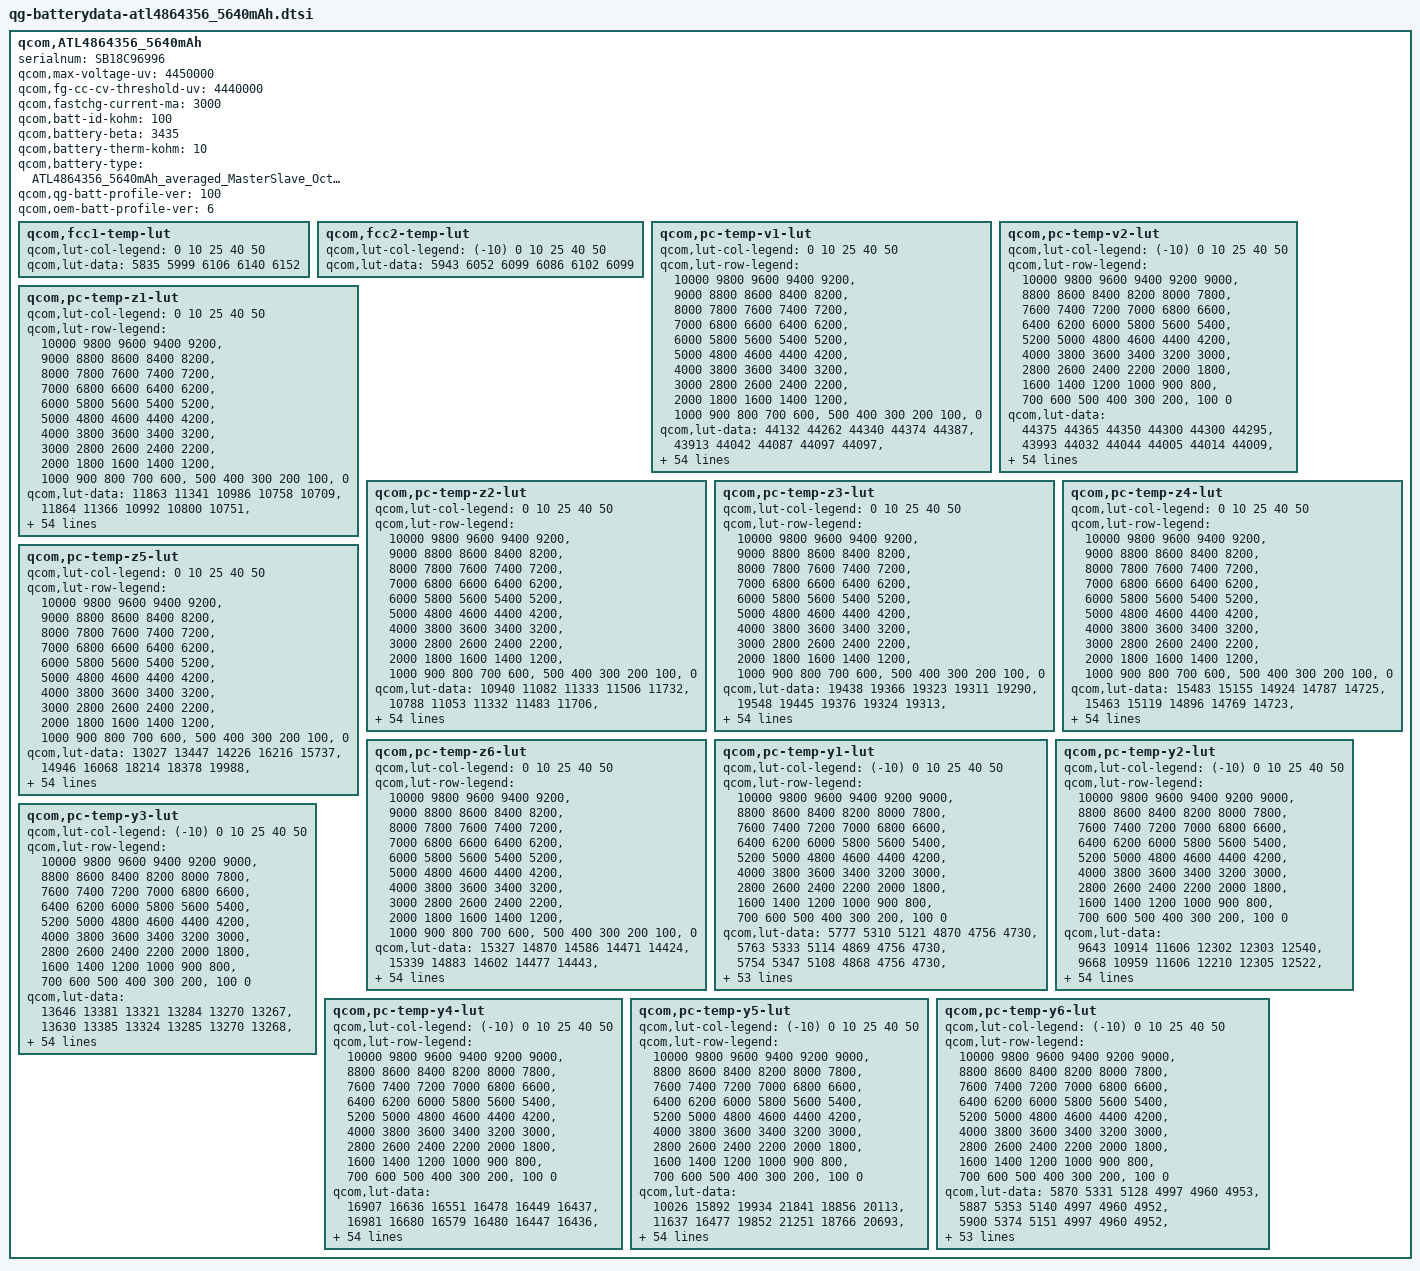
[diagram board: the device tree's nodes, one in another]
qcom,ATL4864356_5640mAh {
	/* ATL4864356_5640mAh_averaged_MasterSlave_Oct14th2020 */
        serialnum = "SB18C96996";
	qcom,max-voltage-uv = <4450000>;
	qcom,fg-cc-cv-threshold-uv = <4440000>;
	qcom,fastchg-current-ma = <3000>;
	qcom,batt-id-kohm = <100>;
	qcom,battery-beta = <3435>;
	qcom,battery-therm-kohm = <10>;
	qcom,battery-type =
		"ATL4864356_5640mAh_averaged_MasterSlave_Oct14th2020";
	qcom,qg-batt-profile-ver = <100>;
        qcom,oem-batt-profile-ver = <6>;

	/*qcom,step-chg-ranges = <3500000  4000000  8000000
				4000001  4200000  6000000
				4200001  4450000  3000000>;
	qcom,ocv-based-step-chg;*/

	qcom,fcc1-temp-lut {
		qcom,lut-col-legend = <0 10 25 40 50>;
		qcom,lut-data = <5835 5999 6106 6140 6152>;
	};

	qcom,fcc2-temp-lut {
		qcom,lut-col-legend = <(-10) 0 10 25 40 50>;
		qcom,lut-data = <5943 6052 6099 6086 6102 6099>;
	};

	qcom,pc-temp-v1-lut {
		qcom,lut-col-legend = <0 10 25 40 50>;
		qcom,lut-row-legend = <10000 9800 9600 9400 9200>,
			<9000 8800 8600 8400 8200>,
			<8000 7800 7600 7400 7200>,
			<7000 6800 6600 6400 6200>,
			<6000 5800 5600 5400 5200>,
			<5000 4800 4600 4400 4200>,
			<4000 3800 3600 3400 3200>,
			<3000 2800 2600 2400 2200>,
			<2000 1800 1600 1400 1200>,
			<1000 900 800 700 600>,
			<500 400 300 200 100>,
			<0>;
		qcom,lut-data = <44132 44262 44340 44374 44387>,
			<43913 44042 44087 44097 44097>,
			<43679 43819 43863 43870 43875>,
			<43448 43598 43649 43662 43662>,
			<43216 43369 43430 43447 43454>,
			<42974 43131 43196 43218 43231>,
			<42729 42888 42954 42983 42998>,
			<42486 42639 42708 42742 42760>,
			<42242 42392 42457 42494 42515>,
			<42004 42147 42210 42248 42269>,
			<41775 41906 41965 42001 42023>,
			<41551 41669 41724 41758 41780>,
			<41328 41438 41486 41521 41544>,
			<41109 41214 41255 41288 41312>,
			<40895 40998 41033 41063 41086>,
			<40691 40787 40819 40843 40863>,
			<40493 40578 40612 40633 40651>,
			<40295 40379 40412 40430 40447>,
			<40104 40199 40224 40238 40254>,
			<39933 40030 40052 40061 40074>,
			<39784 39858 39878 39885 39896>,
			<39635 39688 39692 39690 39701>,
			<39478 39487 39496 39483 39494>,
			<39313 39194 39267 39273 39287>,
			<39123 38932 39015 39053 39074>,
			<38902 38806 38854 38881 38898>,
			<38734 38719 38757 38758 38764>,
			<38627 38638 38671 38652 38650>,
			<38545 38563 38579 38550 38545>,
			<38483 38493 38490 38456 38449>,
			<38435 38428 38412 38370 38361>,
			<38390 38367 38339 38292 38278>,
			<38349 38311 38278 38224 38204>,
			<38311 38260 38225 38163 38138>,
			<38276 38216 38177 38107 38075>,
			<38242 38180 38132 38054 38015>,
			<38208 38143 38087 38001 37954>,
			<38176 38107 38042 37945 37886>,
			<38133 38062 37994 37882 37809>,
			<38054 37986 37921 37804 37722>,
			<37948 37867 37808 37701 37623>,
			<37832 37739 37681 37584 37509>,
			<37695 37599 37543 37450 37375>,
			<37535 37434 37385 37299 37226>,
			<37375 37265 37216 37136 37068>,
			<37248 37155 37106 37039 36975>,
			<37202 37121 37079 37014 36951>,
			<37166 37098 37056 36998 36935>,
			<37132 37074 37037 36980 36917>,
			<37098 37040 37004 36939 36868>,
			<37034 36876 36821 36738 36639>,
			<36759 36467 36397 36303 36195>,
			<36269 35888 35827 35734 35625>,
			<35590 35084 35052 34965 34846>,
			<34486 33721 33864 33791 33657>,
			<30000 30000 30000 30000 30000>;
	};

	qcom,pc-temp-v2-lut {
		qcom,lut-col-legend = <(-10) 0 10 25 40 50>;
		qcom,lut-row-legend = <10000 9800 9600 9400 9200 9000>,
			<8800 8600 8400 8200 8000 7800>,
			<7600 7400 7200 7000 6800 6600>,
			<6400 6200 6000 5800 5600 5400>,
			<5200 5000 4800 4600 4400 4200>,
			<4000 3800 3600 3400 3200 3000>,
			<2800 2600 2400 2200 2000 1800>,
			<1600 1400 1200 1000 900 800>,
			<700 600 500 400 300 200>,
			<100 0>;
		qcom,lut-data = <44375 44365 44350 44300 44300 44295>,
			<43993 44032 44044 44005 44014 44009>,
			<43658 43736 43766 43735 43750 43745>,
			<43382 43485 43522 43494 43512 43508>,
			<43151 43268 43303 43276 43296 43291>,
			<42913 43038 43073 43048 43068 43064>,
			<42654 42792 42829 42807 42828 42826>,
			<42400 42543 42582 42563 42584 42585>,
			<42175 42291 42331 42316 42338 42340>,
			<41956 42040 42081 42069 42092 42094>,
			<41683 41797 41835 41825 41850 41852>,
			<41335 41561 41594 41584 41611 41613>,
			<41094 41329 41360 41349 41377 41378>,
			<40994 41097 41130 41118 41146 41148>,
			<40894 40884 40908 40896 40922 40925>,
			<40594 40710 40695 40681 40704 40709>,
			<40084 40538 40490 40474 40494 40501>,
			<39758 40296 40295 40274 40295 40300>,
			<39573 39990 40104 40082 40103 40107>,
			<39395 39716 39880 39896 39921 39925>,
			<39182 39475 39615 39721 39750 39756>,
			<38966 39252 39368 39523 39553 39563>,
			<38769 39044 39145 39256 39288 39301>,
			<38582 38853 38945 39001 39040 39053>,
			<38442 38682 38776 38829 38869 38881>,
			<38340 38526 38627 38690 38729 38739>,
			<38257 38378 38494 38565 38603 38613>,
			<38189 38230 38374 38452 38492 38500>,
			<38131 38116 38263 38349 38390 38398>,
			<38075 38045 38160 38253 38295 38304>,
			<38022 37991 38066 38166 38209 38217>,
			<37969 37942 37975 38088 38131 38136>,
			<37917 37899 37895 38016 38060 38061>,
			<37861 37855 37845 37948 37994 37993>,
			<37803 37808 37812 37884 37935 37932>,
			<37741 37759 37775 37819 37860 37850>,
			<37677 37706 37737 37755 37760 37726>,
			<37613 37647 37692 37686 37655 37602>,
			<37544 37581 37633 37605 37556 37501>,
			<37469 37505 37559 37520 37464 37409>,
			<37388 37411 37462 37442 37385 37327>,
			<37299 37303 37341 37352 37299 37235>,
			<37206 37186 37184 37224 37171 37111>,
			<37114 37042 37039 37098 37047 36984>,
			<36995 36879 36862 36929 36894 36839>,
			<36889 36753 36765 36879 36858 36808>,
			<36842 36714 36733 36865 36848 36795>,
			<36799 36681 36699 36847 36833 36776>,
			<36760 36649 36650 36819 36803 36748>,
			<36720 36604 36568 36756 36736 36669>,
			<36675 36517 36354 36537 36470 36361>,
			<36588 36239 35895 36075 35990 35863>,
			<36383 35615 35258 35458 35350 35213>,
			<35938 34683 34308 34622 34470 34312>,
			<35152 33420 32821 33356 33149 32962>,
			<34232 31743 28710 29020 29197 28994>;
	};

	qcom,pc-temp-z1-lut {
		qcom,lut-col-legend = <0 10 25 40 50>;
		qcom,lut-row-legend = <10000 9800 9600 9400 9200>,
			<9000 8800 8600 8400 8200>,
			<8000 7800 7600 7400 7200>,
			<7000 6800 6600 6400 6200>,
			<6000 5800 5600 5400 5200>,
			<5000 4800 4600 4400 4200>,
			<4000 3800 3600 3400 3200>,
			<3000 2800 2600 2400 2200>,
			<2000 1800 1600 1400 1200>,
			<1000 900 800 700 600>,
			<500 400 300 200 100>,
			<0>;
		qcom,lut-data = <11863 11341 10986 10758 10709>,
			<11864 11366 10992 10800 10751>,
			<11882 11365 10990 10800 10757>,
			<11870 11346 10980 10799 10757>,
			<11856 11334 10968 10794 10757>,
			<11848 11328 10962 10793 10757>,
			<11840 11323 10959 10792 10760>,
			<11828 11319 10954 10793 10763>,
			<11807 11315 10949 10796 10766>,
			<11796 11307 10948 10796 10767>,
			<11795 11300 10948 10796 10768>,
			<11795 11293 10949 10796 10768>,
			<11786 11287 10948 10796 10768>,
			<11756 11287 10948 10796 10768>,
			<11743 11290 10949 10796 10769>,
			<11747 11291 10950 10797 10770>,
			<11753 11288 10950 10799 10772>,
			<11751 11283 10951 10800 10772>,
			<11743 11282 10951 10801 10773>,
			<11741 11282 10953 10802 10775>,
			<11742 11283 10956 10804 10776>,
			<11745 11286 10958 10805 10778>,
			<11755 11288 10961 10807 10779>,
			<11768 11292 10964 10808 10780>,
			<11773 11296 10967 10810 10782>,
			<11774 11300 10971 10812 10784>,
			<11776 11304 10975 10815 10787>,
			<11780 11308 10979 10818 10789>,
			<11784 11316 10983 10821 10792>,
			<11787 11321 10986 10824 10793>,
			<11789 11324 10990 10826 10795>,
			<11792 11326 10994 10829 10797>,
			<11797 11326 10998 10831 10799>,
			<11804 11327 11001 10834 10801>,
			<11820 11329 11005 10836 10803>,
			<11840 11333 11008 10839 10805>,
			<11848 11338 11012 10841 10806>,
			<11845 11348 11016 10844 10808>,
			<11845 11359 11019 10847 10810>,
			<11861 11366 11023 10849 10811>,
			<11883 11371 11028 10851 10812>,
			<11892 11375 11034 10853 10814>,
			<11901 11382 11039 10855 10815>,
			<11905 11385 11045 10858 10817>,
			<11908 11393 11053 10860 10818>,
			<11914 11407 11061 10864 10819>,
			<11919 11397 11059 10863 10820>,
			<11917 11398 11056 10864 10819>,
			<11917 11402 11057 10864 10820>,
			<11930 11408 11064 10867 10821>,
			<11938 11417 11067 10871 10824>,
			<11965 11432 11074 10876 10828>,
			<11993 11445 11088 10884 10834>,
			<12004 11466 11103 10894 10842>,
			<12004 11466 11103 10894 10842>,
			<12004 11466 11103 10894 10842>;
	};

	qcom,pc-temp-z2-lut {
		qcom,lut-col-legend = <0 10 25 40 50>;
		qcom,lut-row-legend = <10000 9800 9600 9400 9200>,
			<9000 8800 8600 8400 8200>,
			<8000 7800 7600 7400 7200>,
			<7000 6800 6600 6400 6200>,
			<6000 5800 5600 5400 5200>,
			<5000 4800 4600 4400 4200>,
			<4000 3800 3600 3400 3200>,
			<3000 2800 2600 2400 2200>,
			<2000 1800 1600 1400 1200>,
			<1000 900 800 700 600>,
			<500 400 300 200 100>,
			<0>;
		qcom,lut-data = <10940 11082 11333 11506 11732>,
			<10788 11053 11332 11483 11706>,
			<10706 11022 11378 11665 11668>,
			<10671 10957 11363 11638 11721>,
			<10648 10889 11257 11593 11664>,
			<10625 10843 11183 11505 11713>,
			<10605 10801 11139 11456 11622>,
			<10592 10765 11099 11437 11596>,
			<10581 10744 11068 11426 11600>,
			<10573 10731 11072 11428 11604>,
			<10597 10726 11115 11461 11609>,
			<10637 10748 11152 11489 11610>,
			<10630 10796 11175 11493 11526>,
			<10580 10832 11197 11495 11398>,
			<10556 10861 11223 11500 11408>,
			<10573 10887 11249 11511 11494>,
			<10600 10906 11266 11505 11535>,
			<10624 10926 11282 11453 11548>,
			<10651 10965 11297 11427 11561>,
			<10678 11010 11314 11464 11585>,
			<10711 11025 11328 11532 11630>,
			<10737 11032 11337 11645 11759>,
			<10752 11034 11341 11783 11966>,
			<10764 11020 11319 11756 11999>,
			<10774 11005 11267 11536 11936>,
			<10781 11000 11258 11462 11891>,
			<10790 10994 11318 11790 11902>,
			<10808 11001 11374 12061 11908>,
			<10826 11026 11421 11887 11803>,
			<10837 11048 11460 11596 11626>,
			<10846 11060 11429 11526 11522>,
			<10855 11070 11350 11500 11442>,
			<10865 11078 11327 11500 11424>,
			<10874 11085 11326 11553 11473>,
			<10880 11090 11332 11629 11542>,
			<10885 11095 11366 11733 11617>,
			<10894 11101 11411 11836 11710>,
			<10906 11111 11441 11883 11844>,
			<10922 11126 11469 11914 12013>,
			<10941 11150 11507 11958 12111>,
			<10963 11181 11559 12020 12181>,
			<10986 11189 11577 12048 12202>,
			<11015 11184 11563 12015 12055>,
			<11071 11194 11562 11983 11949>,
			<11242 11282 11599 11954 11892>,
			<11471 11649 11755 11911 11995>,
			<11026 11685 11720 11899 11945>,
			<10836 11955 11687 11802 11945>,
			<10841 12353 11678 11826 12002>,
			<10740 12591 11753 11933 12073>,
			<10797 12490 12023 11909 11841>,
			<10619 12236 12183 11716 11573>,
			<10343 11867 12172 11564 11468>,
			<10390 11362 12141 11493 11381>,
			<10390 11362 12141 11493 11381>,
			<10390 11362 12141 11493 11381>;
	};

	qcom,pc-temp-z3-lut {
		qcom,lut-col-legend = <0 10 25 40 50>;
		qcom,lut-row-legend = <10000 9800 9600 9400 9200>,
			<9000 8800 8600 8400 8200>,
			<8000 7800 7600 7400 7200>,
			<7000 6800 6600 6400 6200>,
			<6000 5800 5600 5400 5200>,
			<5000 4800 4600 4400 4200>,
			<4000 3800 3600 3400 3200>,
			<3000 2800 2600 2400 2200>,
			<2000 1800 1600 1400 1200>,
			<1000 900 800 700 600>,
			<500 400 300 200 100>,
			<0>;
		qcom,lut-data = <19438 19366 19323 19311 19290>,
			<19548 19445 19376 19324 19313>,
			<19652 19478 19387 19337 19312>,
			<19689 19529 19385 19336 19321>,
			<19705 19543 19422 19360 19333>,
			<19710 19548 19426 19369 19345>,
			<19713 19549 19427 19370 19345>,
			<19713 19547 19427 19369 19344>,
			<19708 19544 19425 19364 19340>,
			<19704 19538 19421 19360 19337>,
			<19705 19530 19410 19357 19336>,
			<19706 19522 19403 19354 19334>,
			<19702 19513 19401 19349 19328>,
			<19690 19505 19398 19342 19319>,
			<19680 19497 19392 19339 19317>,
			<19672 19493 19385 19335 19316>,
			<19664 19492 19381 19331 19314>,
			<19653 19491 19379 19327 19310>,
			<19639 19485 19377 19324 19307>,
			<19630 19475 19375 19323 19304>,
			<19621 19474 19374 19323 19303>,
			<19618 19475 19379 19327 19306>,
			<19620 19478 19385 19337 19314>,
			<19625 19491 19385 19335 19313>,
			<19630 19502 19381 19318 19299>,
			<19636 19498 19376 19312 19293>,
			<19639 19488 19367 19327 19321>,
			<19637 19482 19363 19343 19347>,
			<19633 19478 19377 19350 19343>,
			<19628 19477 19396 19354 19335>,
			<19622 19479 19401 19353 19328>,
			<19617 19483 19405 19349 19323>,
			<19613 19485 19404 19345 19319>,
			<19609 19488 19398 19340 19316>,
			<19607 19488 19393 19336 19314>,
			<19604 19485 19389 19333 19312>,
			<19600 19481 19387 19332 19310>,
			<19595 19478 19384 19331 19309>,
			<19590 19474 19382 19331 19309>,
			<19586 19470 19379 19331 19309>,
			<19581 19467 19377 19329 19311>,
			<19574 19464 19375 19327 19312>,
			<19563 19459 19372 19324 19309>,
			<19546 19453 19369 19324 19308>,
			<19474 19442 19364 19325 19309>,
			<19306 19398 19350 19313 19298>,
			<19288 19391 19346 19314 19299>,
			<19278 19353 19346 19308 19297>,
			<19275 19309 19344 19307 19296>,
			<19275 19294 19334 19305 19295>,
			<19274 19310 19319 19308 19308>,
			<19276 19298 19308 19316 19314>,
			<19280 19298 19305 19320 19315>,
			<19311 19348 19301 19320 19317>,
			<19311 19348 19301 19320 19317>,
			<19311 19348 19301 19320 19317>;
	};

	qcom,pc-temp-z4-lut {
		qcom,lut-col-legend = <0 10 25 40 50>;
		qcom,lut-row-legend = <10000 9800 9600 9400 9200>,
			<9000 8800 8600 8400 8200>,
			<8000 7800 7600 7400 7200>,
			<7000 6800 6600 6400 6200>,
			<6000 5800 5600 5400 5200>,
			<5000 4800 4600 4400 4200>,
			<4000 3800 3600 3400 3200>,
			<3000 2800 2600 2400 2200>,
			<2000 1800 1600 1400 1200>,
			<1000 900 800 700 600>,
			<500 400 300 200 100>,
			<0>;
		qcom,lut-data = <15483 15155 14924 14787 14725>,
			<15463 15119 14896 14769 14723>,
			<15724 14993 14826 14734 14707>,
			<15564 15116 14780 14710 14683>,
			<15370 15073 14870 14750 14707>,
			<15252 14970 14838 14750 14720>,
			<15155 14908 14793 14726 14703>,
			<15078 14864 14766 14710 14691>,
			<15017 14830 14744 14697 14682>,
			<14963 14804 14730 14688 14674>,
			<14907 14782 14721 14681 14668>,
			<14858 14761 14712 14676 14664>,
			<14832 14743 14703 14673 14664>,
			<14815 14734 14697 14670 14664>,
			<14798 14730 14694 14668 14662>,
			<14774 14725 14692 14663 14654>,
			<14756 14720 14689 14659 14649>,
			<14757 14715 14684 14657 14646>,
			<14762 14710 14680 14654 14643>,
			<14762 14705 14674 14648 14638>,
			<14750 14702 14671 14643 14635>,
			<14739 14700 14674 14647 14638>,
			<14732 14701 14682 14658 14651>,
			<14728 14754 14712 14684 14674>,
			<14738 14808 14775 14742 14723>,
			<14785 14808 14793 14764 14744>,
			<14811 14801 14789 14740 14706>,
			<14814 14793 14781 14711 14668>,
			<14815 14783 14756 14693 14663>,
			<14811 14771 14726 14677 14660>,
			<14800 14757 14710 14670 14657>,
			<14789 14744 14699 14664 14654>,
			<14777 14734 14694 14660 14650>,
			<14766 14725 14691 14657 14645>,
			<14756 14720 14690 14656 14642>,
			<14747 14716 14691 14657 14644>,
			<14738 14713 14691 14660 14648>,
			<14727 14708 14691 14663 14655>,
			<14719 14704 14691 14668 14665>,
			<14714 14703 14692 14672 14666>,
			<14710 14703 14695 14674 14662>,
			<14705 14701 14697 14675 14659>,
			<14700 14691 14689 14671 14657>,
			<14697 14682 14681 14666 14656>,
			<14722 14673 14676 14664 14655>,
			<14839 14658 14651 14649 14646>,
			<14857 14660 14646 14643 14638>,
			<14864 14694 14635 14636 14627>,
			<14862 14738 14630 14624 14616>,
			<14858 14751 14635 14625 14617>,
			<14854 14736 14662 14633 14618>,
			<14860 14758 14680 14632 14615>,
			<14874 14765 14683 14628 14615>,
			<14864 14718 14689 14629 14614>,
			<14864 14718 14689 14629 14614>,
			<14864 14718 14689 14629 14614>;
	};

	qcom,pc-temp-z5-lut {
		qcom,lut-col-legend = <0 10 25 40 50>;
		qcom,lut-row-legend = <10000 9800 9600 9400 9200>,
			<9000 8800 8600 8400 8200>,
			<8000 7800 7600 7400 7200>,
			<7000 6800 6600 6400 6200>,
			<6000 5800 5600 5400 5200>,
			<5000 4800 4600 4400 4200>,
			<4000 3800 3600 3400 3200>,
			<3000 2800 2600 2400 2200>,
			<2000 1800 1600 1400 1200>,
			<1000 900 800 700 600>,
			<500 400 300 200 100>,
			<0>;
		qcom,lut-data = <13027 13447 14226 16216 15737>,
			<14946 16068 18214 18378 19988>,
			<15213 19013 21185 22389 20966>,
			<15772 18150 22327 23670 25908>,
			<16439 18406 19769 22679 24530>,
			<16961 19312 20259 22707 23981>,
			<17489 20087 21043 23324 24669>,
			<18049 20853 21878 23849 24812>,
			<18640 21417 22718 24411 25113>,
			<19320 21857 22933 24562 25507>,
			<20373 22390 22901 24977 26220>,
			<21673 23472 23003 25350 26711>,
			<22706 24805 23967 24960 25234>,
			<23613 25390 24756 24266 22862>,
			<24850 25677 24406 24062 23011>,
			<27414 26215 23813 24021 24400>,
			<29431 28446 23950 24086 24808>,
			<29233 30332 24919 24083 24379>,
			<28515 29761 26044 24180 24080>,
			<28330 28628 27317 25274 24618>,
			<28842 29289 29127 27480 25872>,
			<29832 34218 33871 33082 29595>,
			<34914 40328 38847 41011 35798>,
			<43822 49154 38027 39410 34867>,
			<51098 55600 33567 25913 22839>,
			<58889 50733 29124 19720 17188>,
			<61882 39251 24078 20849 22495>,
			<58711 34067 21697 22398 27373>,
			<53737 31540 23827 24178 27049>,
			<49781 30723 27707 26793 26383>,
			<46036 32086 32111 28853 26429>,
			<44117 34569 37464 30999 27053>,
			<43114 38030 40399 33141 28095>,
			<42656 42587 42006 35311 31027>,
			<42911 44857 43311 37190 33383>,
			<43477 46364 44831 38990 34228>,
			<43814 46979 45798 40211 34715>,
			<43992 46627 45099 39888 33656>,
			<44301 45984 43142 38529 30778>,
			<46419 45330 40899 36389 29657>,
			<48887 44479 37843 32332 29396>,
			<47737 43327 35761 29481 28959>,
			<42990 41614 34811 28194 27130>,
			<38913 41104 33499 27503 25759>,
			<29101 40551 31876 27088 24991>,
			<13678 33216 35679 26579 22661>,
			<13141 29467 32420 27971 24445>,
			<12762 19353 35890 26782 27057>,
			<12636 14702 36399 31264 32777>,
			<12616 13747 27718 29623 32149>,
			<12636 14803 20159 24494 33550>,
			<12689 13832 16586 25232 36984>,
			<12511 13563 15892 26714 36379>,
			<12934 19430 15166 25131 37236>,
			<12934 19430 15166 25131 37236>,
			<12934 19430 15166 25131 37236>;
	};

	qcom,pc-temp-z6-lut {
		qcom,lut-col-legend = <0 10 25 40 50>;
		qcom,lut-row-legend = <10000 9800 9600 9400 9200>,
			<9000 8800 8600 8400 8200>,
			<8000 7800 7600 7400 7200>,
			<7000 6800 6600 6400 6200>,
			<6000 5800 5600 5400 5200>,
			<5000 4800 4600 4400 4200>,
			<4000 3800 3600 3400 3200>,
			<3000 2800 2600 2400 2200>,
			<2000 1800 1600 1400 1200>,
			<1000 900 800 700 600>,
			<500 400 300 200 100>,
			<0>;
		qcom,lut-data = <15327 14870 14586 14471 14424>,
			<15339 14883 14602 14477 14443>,
			<15472 14833 14576 14469 14436>,
			<15397 14898 14552 14457 14431>,
			<15302 14878 14608 14487 14448>,
			<15237 14826 14594 14492 14460>,
			<15180 14792 14574 14483 14454>,
			<15132 14766 14561 14475 14449>,
			<15091 14743 14550 14467 14443>,
			<15056 14723 14539 14461 14439>,
			<15025 14706 14530 14457 14435>,
			<14999 14690 14522 14453 14432>,
			<14977 14676 14517 14448 14428>,
			<14959 14667 14513 14444 14424>,
			<14941 14661 14508 14440 14421>,
			<14922 14656 14504 14436 14418>,
			<14906 14653 14500 14433 14415>,
			<14900 14649 14497 14430 14411>,
			<14895 14643 14494 14427 14408>,
			<14890 14636 14491 14424 14405>,
			<14882 14635 14490 14422 14403>,
			<14877 14636 14493 14425 14406>,
			<14878 14639 14500 14435 14415>,
			<14881 14670 14516 14447 14426>,
			<14890 14700 14540 14464 14441>,
			<14915 14699 14546 14470 14446>,
			<14928 14692 14541 14468 14445>,
			<14930 14686 14536 14465 14443>,
			<14931 14681 14533 14462 14440>,
			<14929 14677 14531 14458 14435>,
			<14922 14673 14529 14454 14430>,
			<14916 14670 14527 14450 14426>,
			<14911 14669 14524 14446 14423>,
			<14906 14667 14520 14442 14418>,
			<14903 14666 14518 14440 14416>,
			<14900 14665 14518 14440 14417>,
			<14898 14663 14517 14440 14417>,
			<14894 14661 14517 14441 14419>,
			<14893 14660 14516 14443 14423>,
			<14896 14661 14516 14445 14424>,
			<14900 14663 14518 14445 14424>,
			<14901 14663 14519 14445 14424>,
			<14902 14661 14515 14442 14421>,
			<14900 14658 14512 14440 14420>,
			<14888 14654 14509 14440 14421>,
			<14861 14631 14493 14428 14411>,
			<14860 14629 14489 14426 14408>,
			<14861 14625 14486 14420 14403>,
			<14859 14623 14483 14414 14397>,
			<14861 14624 14481 14414 14397>,
			<14866 14630 14487 14421 14405>,
			<14878 14637 14492 14425 14408>,
			<14894 14648 14495 14427 14410>,
			<14919 14665 14500 14429 14412>,
			<14919 14665 14500 14429 14412>,
			<14919 14665 14500 14429 14412>;
	};

	qcom,pc-temp-y1-lut {
		qcom,lut-col-legend = <(-10) 0 10 25 40 50>;
		qcom,lut-row-legend = <10000 9800 9600 9400 9200 9000>,
			<8800 8600 8400 8200 8000 7800>,
			<7600 7400 7200 7000 6800 6600>,
			<6400 6200 6000 5800 5600 5400>,
			<5200 5000 4800 4600 4400 4200>,
			<4000 3800 3600 3400 3200 3000>,
			<2800 2600 2400 2200 2000 1800>,
			<1600 1400 1200 1000 900 800>,
			<700 600 500 400 300 200>,
			<100 0>;
		qcom,lut-data = <5777 5310 5121 4870 4756 4730>,
			<5763 5333 5114 4869 4756 4730>,
			<5754 5347 5108 4868 4756 4730>,
			<5750 5354 5102 4867 4756 4730>,
			<5749 5356 5097 4866 4755 4729>,
			<5752 5355 5093 4864 4755 4729>,
			<5760 5345 5090 4862 4754 4729>,
			<5769 5338 5088 4860 4753 4728>,
			<5778 5337 5086 4857 4751 4728>,
			<5785 5337 5085 4854 4750 4727>,
			<5783 5340 5085 4854 4750 4726>,
			<5766 5345 5086 4853 4749 4726>,
			<5755 5348 5086 4853 4749 4727>,
			<5759 5351 5084 4851 4749 4727>,
			<5764 5352 5082 4850 4748 4727>,
			<5765 5353 5083 4850 4749 4727>,
			<5764 5353 5083 4852 4749 4727>,
			<5764 5352 5082 4852 4749 4728>,
			<5766 5350 5079 4852 4749 4728>,
			<5766 5350 5079 4853 4749 4729>,
			<5771 5352 5081 4854 4750 4729>,
			<5777 5354 5082 4856 4751 4730>,
			<5777 5357 5081 4857 4752 4730>,
			<5773 5362 5080 4858 4753 4731>,
			<5771 5367 5082 4861 4754 4731>,
			<5772 5372 5086 4864 4756 4733>,
			<5775 5372 5087 4866 4757 4733>,
			<5779 5365 5087 4868 4758 4734>,
			<5783 5360 5088 4869 4759 4734>,
			<5783 5362 5091 4873 4761 4735>,
			<5783 5366 5095 4876 4763 4736>,
			<5782 5365 5097 4880 4764 4737>,
			<5780 5362 5098 4884 4765 4739>,
			<5778 5362 5102 4888 4767 4740>,
			<5772 5366 5106 4891 4769 4742>,
			<5763 5368 5107 4893 4771 4743>,
			<5761 5364 5104 4894 4773 4744>,
			<5769 5358 5103 4896 4774 4745>,
			<5778 5358 5109 4896 4775 4746>,
			<5786 5360 5117 4897 4776 4747>,
			<5789 5377 5123 4899 4776 4748>,
			<5780 5389 5124 4903 4778 4748>,
			<5783 5396 5124 4908 4779 4749>,
			<5819 5390 5128 4911 4781 4751>,
			<5824 5403 5135 4920 4783 4752>,
			<5844 5416 5137 4916 4784 4752>,
			<5835 5413 5137 4923 4786 4753>,
			<5849 5423 5137 4923 4785 4753>,
			<5828 5419 5139 4926 4786 4754>,
			<5867 5423 5154 4925 4787 4754>,
			<5887 5461 5159 4935 4787 4755>,
			<5951 5478 5168 4945 4790 4757>,
			<6043 5603 5217 4954 4795 4761>,
			<6172 5693 5305 4970 4802 4766>,
			<6172 5693 5305 4970 4802 4766>,
			<6172 5693 5305 4970 4802 4766>;
	};

	qcom,pc-temp-y2-lut {
		qcom,lut-col-legend = <(-10) 0 10 25 40 50>;
		qcom,lut-row-legend = <10000 9800 9600 9400 9200 9000>,
			<8800 8600 8400 8200 8000 7800>,
			<7600 7400 7200 7000 6800 6600>,
			<6400 6200 6000 5800 5600 5400>,
			<5200 5000 4800 4600 4400 4200>,
			<4000 3800 3600 3400 3200 3000>,
			<2800 2600 2400 2200 2000 1800>,
			<1600 1400 1200 1000 900 800>,
			<700 600 500 400 300 200>,
			<100 0>;
		qcom,lut-data = <9643 10914 11606 12302 12303 12540>,
			<9668 10959 11606 12210 12305 12522>,
			<9937 11026 11598 12117 12287 12494>,
			<10223 11095 11585 12032 12254 12456>,
			<10447 11143 11568 11962 12210 12409>,
			<10534 11154 11546 11912 12158 12337>,
			<10555 11146 11508 11874 12084 12146>,
			<10573 11138 11469 11852 12029 12037>,
			<10625 11137 11429 11845 11994 12049>,
			<10696 11138 11399 11839 11971 12070>,
			<10682 11123 11395 11825 11977 12098>,
			<10484 11091 11395 11807 11999 12132>,
			<10381 11105 11401 11802 12012 12129>,
			<10590 11320 11425 11803 12020 12064>,
			<10795 11468 11463 11808 12031 12029>,
			<10505 11384 11561 11832 12051 12094>,
			<9880 11272 11672 11876 12077 12172>,
			<9704 11318 11738 11943 12114 12207>,
			<9698 11476 11784 12042 12182 12252>,
			<9694 11524 11788 12145 12284 12316>,
			<9689 11524 11769 12266 12458 12445>,
			<9683 11523 11760 12313 12524 12510>,
			<9680 11532 11763 12233 12446 12498>,
			<9677 11543 11768 12152 12370 12479>,
			<9675 11537 11798 12156 12383 12496>,
			<9673 11504 11851 12176 12418 12532>,
			<9672 11406 11873 12206 12453 12555>,
			<9671 10967 11885 12262 12495 12604>,
			<9670 10683 11891 12301 12550 12629>,
			<9669 10684 11879 12317 12650 12741>,
			<9667 10685 11869 12332 12717 12841>,
			<9666 10658 11895 12365 12718 12848>,
			<9666 10560 11934 12400 12713 12855>,
			<9665 10398 11916 12388 12767 12922>,
			<9664 9978 11822 12319 12900 13082>,
			<9664 9726 11729 12280 12923 13120>,
			<9664 9700 11643 12271 12749 12934>,
			<9663 9686 11550 12268 12601 12793>,
			<9663 9678 11450 12273 12558 12836>,
			<9663 9673 11331 12270 12547 12872>,
			<9663 9670 11184 12257 12569 12764>,
			<9662 9667 10992 12221 12634 12635>,
			<9662 9667 10723 12229 12594 12731>,
			<9662 9664 10446 12183 12691 12734>,
			<9661 9662 9930 12044 12495 12725>,
			<9661 9661 9767 11893 12421 12543>,
			<9660 9660 9720 11869 12331 12499>,
			<9660 9659 9693 11853 12365 12331>,
			<9658 9659 9678 11787 12229 12219>,
			<9657 9658 9669 11734 12211 12230>,
			<9654 9656 9663 11643 12223 12149>,
			<9650 9651 9658 11493 12117 12040>,
			<9649 9649 9655 11334 11990 11923>,
			<9648 9649 9652 11166 11848 11815>,
			<9648 9649 9652 11166 11848 11815>,
			<9648 9649 9652 11166 11848 11815>;
	};

	qcom,pc-temp-y3-lut {
		qcom,lut-col-legend = <(-10) 0 10 25 40 50>;
		qcom,lut-row-legend = <10000 9800 9600 9400 9200 9000>,
			<8800 8600 8400 8200 8000 7800>,
			<7600 7400 7200 7000 6800 6600>,
			<6400 6200 6000 5800 5600 5400>,
			<5200 5000 4800 4600 4400 4200>,
			<4000 3800 3600 3400 3200 3000>,
			<2800 2600 2400 2200 2000 1800>,
			<1600 1400 1200 1000 900 800>,
			<700 600 500 400 300 200>,
			<100 0>;
		qcom,lut-data = <13646 13381 13321 13284 13270 13267>,
			<13630 13385 13324 13285 13270 13268>,
			<13611 13391 13327 13285 13270 13268>,
			<13592 13397 13330 13286 13271 13269>,
			<13577 13402 13332 13287 13271 13269>,
			<13569 13404 13334 13288 13272 13270>,
			<13564 13404 13336 13289 13272 13270>,
			<13561 13405 13337 13290 13273 13271>,
			<13561 13406 13338 13291 13273 13271>,
			<13561 13408 13339 13291 13273 13271>,
			<13549 13408 13340 13291 13275 13272>,
			<13499 13406 13341 13290 13279 13272>,
			<13469 13402 13342 13290 13279 13272>,
			<13465 13388 13344 13290 13279 13272>,
			<13463 13379 13344 13290 13279 13272>,
			<13460 13378 13336 13292 13278 13274>,
			<13453 13377 13328 13295 13278 13276>,
			<13453 13375 13329 13294 13278 13276>,
			<13460 13372 13331 13293 13280 13276>,
			<13465 13367 13330 13293 13282 13276>,
			<13460 13360 13324 13296 13283 13279>,
			<13451 13353 13319 13296 13284 13280>,
			<13445 13348 13315 13291 13279 13276>,
			<13441 13343 13313 13285 13274 13271>,
			<13440 13340 13311 13285 13273 13270>,
			<13447 13336 13309 13285 13273 13269>,
			<13459 13330 13308 13284 13273 13268>,
			<13478 13311 13307 13284 13273 13268>,
			<13506 13297 13306 13284 13273 13268>,
			<13536 13303 13305 13283 13272 13269>,
			<13571 13315 13304 13283 13272 13269>,
			<13609 13322 13301 13283 13272 13269>,
			<13650 13328 13297 13284 13272 13268>,
			<13693 13336 13297 13284 13273 13268>,
			<13735 13348 13302 13283 13274 13269>,
			<13779 13365 13306 13283 13274 13270>,
			<13824 13388 13309 13283 13273 13268>,
			<13871 13419 13312 13283 13272 13267>,
			<13914 13455 13316 13281 13271 13267>,
			<13949 13497 13319 13280 13270 13267>,
			<13982 13542 13321 13280 13270 13267>,
			<14014 13593 13324 13281 13272 13267>,
			<14040 13581 13315 13280 13269 13268>,
			<14015 13657 13322 13281 13270 13268>,
			<14077 13766 13333 13282 13269 13267>,
			<14171 13913 13366 13285 13270 13269>,
			<14227 13994 13392 13288 13273 13269>,
			<14301 14083 13430 13290 13275 13270>,
			<14420 14185 13487 13294 13277 13274>,
			<14626 14312 13586 13298 13280 13275>,
			<15202 14605 13767 13299 13279 13273>,
			<17733 16281 14120 13300 13279 13273>,
			<25390 24443 14766 13308 13279 13274>,
			<57216 65535 19157 13319 13281 13276>,
			<57216 65535 19157 13319 13281 13276>,
			<57216 65535 19157 13319 13281 13276>;
	};

	qcom,pc-temp-y4-lut {
		qcom,lut-col-legend = <(-10) 0 10 25 40 50>;
		qcom,lut-row-legend = <10000 9800 9600 9400 9200 9000>,
			<8800 8600 8400 8200 8000 7800>,
			<7600 7400 7200 7000 6800 6600>,
			<6400 6200 6000 5800 5600 5400>,
			<5200 5000 4800 4600 4400 4200>,
			<4000 3800 3600 3400 3200 3000>,
			<2800 2600 2400 2200 2000 1800>,
			<1600 1400 1200 1000 900 800>,
			<700 600 500 400 300 200>,
			<100 0>;
		qcom,lut-data = <16907 16636 16551 16478 16449 16437>,
			<16981 16680 16579 16480 16447 16436>,
			<17073 16758 16618 16481 16445 16434>,
			<17163 16842 16656 16482 16445 16433>,
			<17226 16903 16682 16482 16444 16432>,
			<17242 16916 16687 16482 16444 16432>,
			<17227 16912 16682 16480 16445 16432>,
			<17211 16907 16676 16480 16447 16433>,
			<17205 16900 16669 16481 16449 16434>,
			<17201 16895 16663 16483 16452 16435>,
			<17209 16896 16662 16488 16451 16437>,
			<17254 16904 16663 16495 16450 16439>,
			<17298 16918 16664 16502 16451 16443>,
			<17359 16959 16669 16509 16456 16448>,
			<17408 17001 16677 16516 16463 16452>,
			<17319 17038 16723 16524 16470 16453>,
			<17088 17066 16770 16533 16479 16455>,
			<16993 17029 16777 16550 16486 16459>,
			<16970 16905 16780 16574 16493 16468>,
			<16946 16825 16770 16596 16508 16480>,
			<16897 16784 16713 16618 16535 16499>,
			<16839 16748 16657 16624 16544 16505>,
			<16788 16712 16613 16561 16504 16477>,
			<16741 16677 16579 16492 16462 16448>,
			<16726 16645 16561 16478 16451 16441>,
			<16724 16616 16549 16471 16445 16437>,
			<16724 16597 16541 16470 16444 16437>,
			<16724 16586 16536 16472 16446 16439>,
			<16726 16581 16531 16475 16449 16442>,
			<16728 16580 16523 16479 16454 16445>,
			<16733 16579 16516 16484 16461 16450>,
			<16737 16587 16505 16489 16468 16456>,
			<16740 16602 16496 16495 16475 16463>,
			<16743 16618 16497 16497 16483 16470>,
			<16748 16640 16507 16499 16491 16476>,
			<16755 16660 16520 16499 16491 16476>,
			<16761 16674 16539 16491 16474 16458>,
			<16765 16685 16558 16479 16456 16444>,
			<16768 16690 16575 16467 16447 16442>,
			<16767 16693 16586 16461 16444 16441>,
			<16765 16688 16591 16466 16444 16440>,
			<16759 16677 16585 16471 16445 16440>,
			<16748 16648 16559 16460 16442 16434>,
			<16723 16643 16574 16469 16444 16434>,
			<16721 16643 16596 16463 16433 16424>,
			<16722 16650 16616 16473 16441 16432>,
			<16728 16663 16635 16485 16446 16438>,
			<16738 16677 16657 16497 16450 16442>,
			<16745 16696 16690 16511 16456 16453>,
			<16757 16724 16736 16526 16476 16476>,
			<16788 16755 16767 16522 16451 16442>,
			<17124 16888 16788 16523 16443 16435>,
			<18424 19042 16842 16551 16452 16444>,
			<28673 49778 18778 16599 16479 16468>,
			<28673 49778 18778 16599 16479 16468>,
			<28673 49778 18778 16599 16479 16468>;
	};

	qcom,pc-temp-y5-lut {
		qcom,lut-col-legend = <(-10) 0 10 25 40 50>;
		qcom,lut-row-legend = <10000 9800 9600 9400 9200 9000>,
			<8800 8600 8400 8200 8000 7800>,
			<7600 7400 7200 7000 6800 6600>,
			<6400 6200 6000 5800 5600 5400>,
			<5200 5000 4800 4600 4400 4200>,
			<4000 3800 3600 3400 3200 3000>,
			<2800 2600 2400 2200 2000 1800>,
			<1600 1400 1200 1000 900 800>,
			<700 600 500 400 300 200>,
			<100 0>;
		qcom,lut-data = <10026 15892 19934 21841 18856 20113>,
			<11637 16477 19852 21251 18766 20693>,
			<13329 17066 19749 20678 18586 21024>,
			<14933 17616 19668 20180 18362 21156>,
			<16282 18084 19649 19820 18139 21141>,
			<17213 18440 19734 19659 17935 21008>,
			<17848 18771 19909 19675 17600 20661>,
			<18416 18927 19999 19631 17260 20295>,
			<19340 18894 19820 19188 16840 20007>,
			<20363 18821 19499 18477 16503 19682>,
			<19807 18719 19162 17640 17213 19229>,
			<16235 18544 18777 16600 18964 18637>,
			<14457 18165 18565 15985 19262 17921>,
			<17816 16867 18423 15587 18360 16935>,
			<21490 16046 18190 15440 17358 16515>,
			<19953 18036 17191 15592 16323 17439>,
			<15756 20983 16271 15776 15623 18419>,
			<14788 21923 17526 15716 15722 17980>,
			<16214 22416 20498 15546 16090 16990>,
			<17162 22714 21997 16276 16602 16951>,
			<16906 22920 22795 20262 17502 17920>,
			<16347 23108 23329 22482 18645 19209>,
			<15519 23364 23731 22615 20417 21388>,
			<14221 23609 24006 22719 21924 22925>,
			<13433 23951 24178 23230 22639 22518>,
			<12973 24635 24293 23995 23150 21534>,
			<12721 24283 24325 24018 22947 20583>,
			<12736 19500 24510 23412 21988 19530>,
			<12839 15780 24770 22880 21076 19183>,
			<12936 14878 25354 22481 20111 19698>,
			<13073 14378 25742 22257 19579 20049>,
			<13233 14450 23379 22896 19678 19442>,
			<13491 14679 19661 24199 19945 18616>,
			<13706 14687 19508 24843 20711 19018>,
			<13735 14375 20634 25207 22316 20624>,
			<13723 14269 21109 25542 22971 21146>,
			<13791 14448 21168 25936 23138 20859>,
			<14040 14656 21184 26157 23217 20613>,
			<14195 14873 21051 24148 22752 20721>,
			<14218 15044 20774 21339 22141 20870>,
			<14215 14911 20244 20019 21374 20618>,
			<14013 14649 19579 20550 22504 20377>,
			<13780 14406 17308 20938 19071 21353>,
			<13178 13995 16778 20377 18653 20507>,
			<12758 13848 14873 21209 21234 25237>,
			<12721 13760 14684 21442 18759 20640>,
			<12648 13576 14731 21023 19560 18905>,
			<12531 13736 14731 20227 20251 18501>,
			<12660 13957 14517 19597 20101 22634>,
			<12761 13978 14335 19756 22574 22941>,
			<12847 14129 14299 20751 25326 23745>,
			<11310 12454 13944 21100 29768 24693>,
			<9934 9708 13603 21805 26777 25976>,
			<9105 8893 10175 21977 26833 27425>,
			<9105 8893 10175 21977 26833 27425>,
			<9105 8893 10175 21977 26833 27425>;
	};

	qcom,pc-temp-y6-lut {
		qcom,lut-col-legend = <(-10) 0 10 25 40 50>;
		qcom,lut-row-legend = <10000 9800 9600 9400 9200 9000>,
			<8800 8600 8400 8200 8000 7800>,
			<7600 7400 7200 7000 6800 6600>,
			<6400 6200 6000 5800 5600 5400>,
			<5200 5000 4800 4600 4400 4200>,
			<4000 3800 3600 3400 3200 3000>,
			<2800 2600 2400 2200 2000 1800>,
			<1600 1400 1200 1000 900 800>,
			<700 600 500 400 300 200>,
			<100 0>;
		qcom,lut-data = <5870 5331 5128 4997 4960 4953>,
			<5887 5353 5140 4997 4960 4952>,
			<5900 5374 5151 4997 4960 4952>,
			<5909 5390 5158 4998 4960 4952>,
			<5914 5400 5163 4998 4961 4953>,
			<5914 5401 5163 4998 4961 4953>,
			<5903 5395 5160 4998 4962 4953>,
			<5889 5389 5156 4998 4962 4954>,
			<5883 5386 5153 4999 4963 4955>,
			<5878 5383 5150 4999 4964 4955>,
			<5864 5381 5148 5000 4965 4956>,
			<5830 5379 5146 5001 4967 4957>,
			<5814 5378 5146 5003 4968 4958>,
			<5842 5380 5147 5005 4970 4959>,
			<5872 5383 5148 5007 4971 4961>,
			<5835 5393 5155 5010 4973 4962>,
			<5743 5403 5162 5015 4975 4964>,
			<5717 5392 5165 5020 4977 4966>,
			<5718 5356 5166 5026 4981 4968>,
			<5718 5332 5163 5032 4986 4972>,
			<5709 5317 5142 5040 4995 4979>,
			<5694 5305 5123 5042 4997 4981>,
			<5685 5295 5109 5020 4982 4970>,
			<5678 5287 5098 4997 4967 4959>,
			<5677 5282 5093 4993 4963 4955>,
			<5689 5278 5089 4991 4961 4953>,
			<5707 5274 5088 4991 4961 4953>,
			<5728 5268 5088 4991 4962 4954>,
			<5754 5265 5087 4992 4962 4955>,
			<5782 5274 5087 4994 4964 4956>,
			<5813 5292 5086 4996 4966 4958>,
			<5846 5312 5084 4998 4968 4960>,
			<5881 5337 5082 5001 4970 4961>,
			<5918 5365 5084 5002 4973 4963>,
			<5954 5399 5094 5003 4976 4966>,
			<5989 5437 5105 5003 4977 4966>,
			<6027 5481 5120 5001 4971 4960>,
			<6067 5528 5136 4999 4965 4955>,
			<6103 5577 5155 4995 4962 4955>,
			<6133 5627 5175 4992 4961 4955>,
			<6159 5677 5197 4994 4962 4955>,
			<6182 5728 5214 4998 4963 4955>,
			<6203 5715 5199 4995 4960 4953>,
			<6188 5783 5234 4999 4961 4954>,
			<6241 5878 5283 4999 4958 4951>,
			<6319 6006 5356 5006 4961 4954>,
			<6368 6078 5407 5013 4965 4956>,
			<6434 6160 5472 5019 4968 4958>,
			<6540 6251 5557 5027 4971 4964>,
			<6726 6369 5680 5036 4979 4972>,
			<7231 6629 5864 5038 4971 4960>,
			<9322 8009 6177 5043 4969 4959>,
			<15162 14491 6730 5064 4972 4963>,
			<37211 56162 10603 5097 4982 4972>,
			<37211 56162 10603 5097 4982 4972>,
			<37211 56162 10603 5097 4982 4972>;
	};

};
